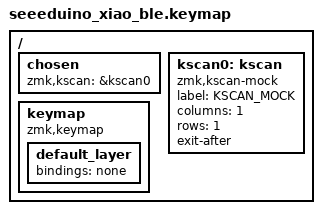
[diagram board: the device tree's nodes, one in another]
#include <behaviors.dtsi>
#include <dt-bindings/zmk/keys.h>

/ {
    chosen {
        zmk,kscan = &kscan0;
    };

    kscan0: kscan {
        compatible = "zmk,kscan-mock";
        label = "KSCAN_MOCK";
        columns = <1>;
        rows = <1>; 
        exit-after;
    };

    keymap {
        compatible = "zmk,keymap";

        default_layer {
            bindings = <
                &none
            >;
        };
    };
};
